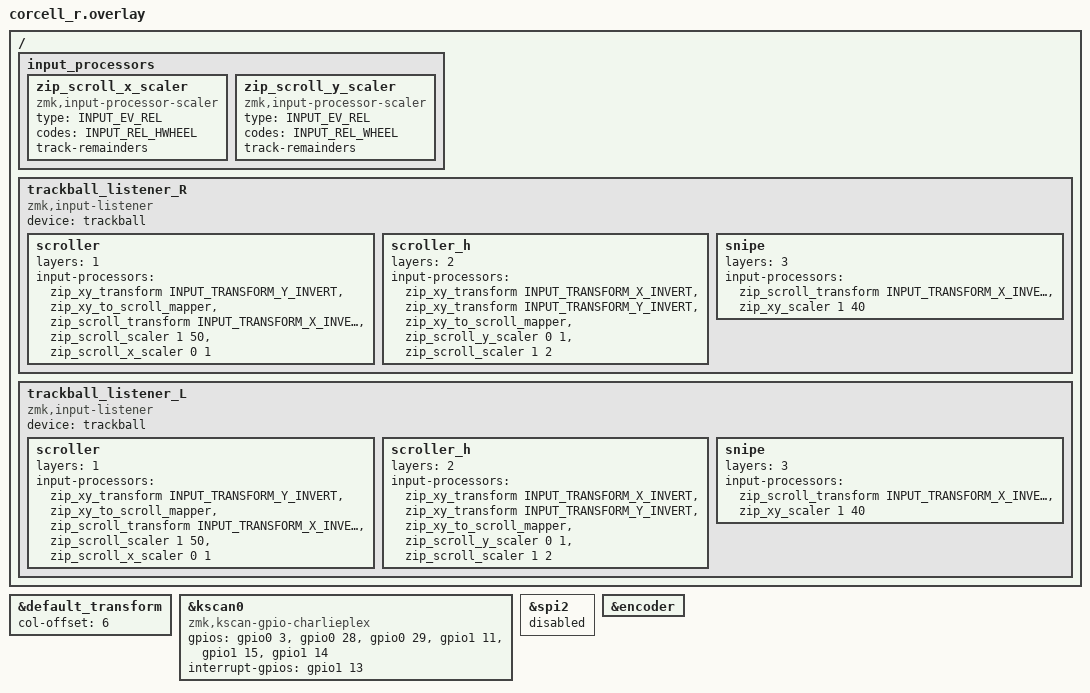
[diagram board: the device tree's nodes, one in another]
#include "corcell.dtsi"

#include <dt-bindings/input/input-event-codes.h>
#include <zephyr/dt-bindings/input/input-event-codes.h>
#include <input/processors.dtsi>
#include <dt-bindings/zmk/input_transform.h>


/ {
    input_processors {
        zip_scroll_x_scaler: zip_scroll_x_scaler {
            compatible = "zmk,input-processor-scaler";
            #input-processor-cells = <2>;
            type = <INPUT_EV_REL>;
            codes = <INPUT_REL_HWHEEL>;
            track-remainders;
        };
    };
};


 / {
    input_processors {
        zip_scroll_y_scaler: zip_scroll_y_scaler {
            compatible = "zmk,input-processor-scaler";
            #input-processor-cells = <2>;
            type = <INPUT_EV_REL>;
            codes = <INPUT_REL_WHEEL>;
            track-remainders;
        };
    };
};





&default_transform {
    col-offset = <6>;
};

&kscan0 {
    compatible = "zmk,kscan-gpio-charlieplex";
    gpios
        = <&gpio0 3 (GPIO_ACTIVE_HIGH)>
        , <&gpio0 28 (GPIO_ACTIVE_HIGH)>
        , <&gpio0 29 (GPIO_ACTIVE_HIGH)>
        , <&gpio1 11 (GPIO_ACTIVE_HIGH)>
        , <&gpio1 15 (GPIO_ACTIVE_HIGH)>
        , <&gpio1 14 (GPIO_ACTIVE_HIGH)>
        ;
    interrupt-gpios = <&gpio1 13 (GPIO_ACTIVE_HIGH | GPIO_PULL_DOWN)>;
};

&spi2 {
    status = "disabled";
};

/* On-board rotary encoder on RE_A/RE_B. An FPC encoder snippet moves these pins. */
&encoder {
    status = "okay";
};





/ {
    trackball_listener_R {
        compatible = "zmk,input-listener";
        device = <&trackball>;


  scroller {
        layers = <1>;
        input-processors = 
            // <&zip_xy_transform INPUT_TRANSFORM_XY_SWAP>,        //X軸とY軸の入れ替え
            // <&zip_xy_transform INPUT_TRANSFORM_X_INVERT>,       //X軸反転
            <&zip_xy_transform INPUT_TRANSFORM_Y_INVERT>,       //Y軸反転
            <&zip_xy_to_scroll_mapper>,                         //スクロールモードに変更
            <&zip_scroll_transform INPUT_TRANSFORM_X_INVERT>,   //スクロールのX軸反転
            //<&zip_scroll_transform INPUT_TRANSFORM_Y_INVERT>,   //スクロールのY軸反転
            <&zip_scroll_scaler 1 50>,                           //スクロール量を1/14倍
            <&zip_scroll_x_scaler 0 1>;
    };

    scroller_h {
        layers = <2>;
        input-processors = 
            // <&zip_xy_transform INPUT_TRANSFORM_XY_SWAP>,        //X軸とY軸の入れ替え
            <&zip_xy_transform INPUT_TRANSFORM_X_INVERT>,       //X軸反転
            <&zip_xy_transform INPUT_TRANSFORM_Y_INVERT>,       //Y軸反転
            <&zip_xy_to_scroll_mapper>,                         //スクロールモードに変更
            //<&zip_scroll_transform INPUT_TRANSFORM_X_INVERT>,   //スクロールのX軸反転
            <&zip_scroll_y_scaler 0 1>,
            //<&zip_scroll_transform INPUT_TRANSFORM_Y_INVERT>,   //スクロールのY軸反転
            <&zip_scroll_scaler 1 2>;                           //スクロール量を1/8倍
    };


    snipe {
        layers = <3>;
        input-processors = 
            
            <&zip_scroll_transform INPUT_TRANSFORM_X_INVERT>,   //スクロールのX軸反転
            
            <&zip_xy_scaler 1 40>;                           //スクロール量を1/8倍
    };





    };
};



/ {
    trackball_listener_L {
        compatible = "zmk,input-listener";
        device = <&trackball>;


  scroller {
        layers = <1>;
        input-processors = 
            // <&zip_xy_transform INPUT_TRANSFORM_XY_SWAP>,        //X軸とY軸の入れ替え
            // <&zip_xy_transform INPUT_TRANSFORM_X_INVERT>,       //X軸反転
            <&zip_xy_transform INPUT_TRANSFORM_Y_INVERT>,       //Y軸反転
            <&zip_xy_to_scroll_mapper>,                         //スクロールモードに変更
            <&zip_scroll_transform INPUT_TRANSFORM_X_INVERT>,   //スクロールのX軸反転
            //<&zip_scroll_transform INPUT_TRANSFORM_Y_INVERT>,   //スクロールのY軸反転
            <&zip_scroll_scaler 1 50>,                           //スクロール量を1/14倍
            <&zip_scroll_x_scaler 0 1>;
    };

    scroller_h {
        layers = <2>;
        input-processors = 
            // <&zip_xy_transform INPUT_TRANSFORM_XY_SWAP>,        //X軸とY軸の入れ替え
            <&zip_xy_transform INPUT_TRANSFORM_X_INVERT>,       //X軸反転
            <&zip_xy_transform INPUT_TRANSFORM_Y_INVERT>,       //Y軸反転
            <&zip_xy_to_scroll_mapper>,                         //スクロールモードに変更
            //<&zip_scroll_transform INPUT_TRANSFORM_X_INVERT>,   //スクロールのX軸反転
            <&zip_scroll_y_scaler 0 1>,
            //<&zip_scroll_transform INPUT_TRANSFORM_Y_INVERT>,   //スクロールのY軸反転
            <&zip_scroll_scaler 1 2>;                           //スクロール量を1/8倍
    };


    snipe {
        layers = <3>;
        input-processors = 
            
            <&zip_scroll_transform INPUT_TRANSFORM_X_INVERT>,   //スクロールのX軸反転
            
            <&zip_xy_scaler 1 40>;                           //スクロール量を1/8倍
    };





    };
};



